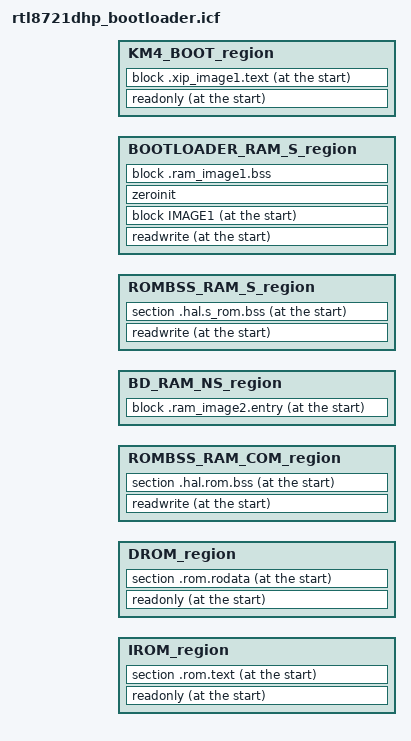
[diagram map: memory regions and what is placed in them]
/*###ICF### Section handled by ICF editor, don't touch! ****/
/*-Editor annotation file-*/
/* IcfEditorFile="$TOOLKIT_DIR$\config\ide\IcfEditor\cortex_v1_0.xml" */
/*-Specials-*/

include "rtl8721dhp_rom_symbol_boot.icf";
include "rtl8721d_memory_layout_tz.icf";

/*-Sizes-*/
/*define symbol __ICFEDIT_size_cstack__   = 0x400;*/
/*define symbol __ICFEDIT_size_heap__     = 0x800;*/
/**** End of ICF editor section. ###ICF###*/

define memory mem with size = 4G;
define region IROM_region   		= mem:[from __ICFEDIT_region_HS_IROM_start__   to __ICFEDIT_region_HS_IROM_end__];
define region IROM_NS_region   		= mem:[from __ICFEDIT_region_HS_IROM_NS_start__   to __ICFEDIT_region_HS_IROM_NS_end__];
define region DROM_NS_region   		= mem:[from __ICFEDIT_region_HS_DROM_NS_start__   to __ICFEDIT_region_HS_DROM_NS_end__];
define region DROM_region  		= mem:[from __ICFEDIT_region_HS_DROM_start__   to __ICFEDIT_region_HS_DROM_end__];
define region ROMBSS_RAM_COM_region   	= mem:[from __ICFEDIT_region_HS_ROMBSS_RAM_COM_start__   to __ICFEDIT_region_HS_ROMBSS_RAM_COM_end__];
define region ROMBSS_RAM_NS_region   	= mem:[from __ICFEDIT_region_HS_ROMBSS_RAM_NS_start__   to __ICFEDIT_region_HS_ROMBSS_RAM_NS_end__];
define region RSVD_RAM_NS_region   	= mem:[from __ICFEDIT_region_HS_RSVD_RAM_NS_start__   to __ICFEDIT_region_HS_RSVD_RAM_NS_end__];
define region MSP_RAM_NS_region   	= mem:[from __ICFEDIT_region_HS_MSP_RAM_NS_start__   to __ICFEDIT_region_HS_MSP_RAM_NS_end__];
define region BD_RAM_NS_region   	= mem:[from __ICFEDIT_region_HS_BD_RAM_NS_start__   to __ICFEDIT_region_HS_BD_RAM_NS_end__];
define region BD_RAM_S_region   	= mem:[from __ICFEDIT_region_HS_BD_RAM_S_start__   to __ICFEDIT_region_HS_BD_RAM_S_end__];
define region BD_RAM_NSC_region   	= mem:[from __ICFEDIT_region_HS_BD_RAM_NSC_start__   to __ICFEDIT_region_HS_BD_RAM_NSC_end__];
define region ROMBSS_RAM_S_region   	= mem:[from __ICFEDIT_region_HS_ROMBSS_RAM_S_start__   to __ICFEDIT_region_HS_ROMBSS_RAM_S_end__];
define region BOOTLOADER_RAM_S_region   = mem:[from __ICFEDIT_region_HS_BOOTLOADER_RAM_S_start__   to __ICFEDIT_region_HS_BOOTLOADER_RAM_S_end__];
define region MSP_RAM_S_region   	= mem:[from __ICFEDIT_region_HS_MSP_RAM_S_start__   to __ICFEDIT_region_HS_MSP_RAM_S_end__];
define region EXTENTION_SRAM_region   	= mem:[from __ICFEDIT_region_HS_EXTENTION_SRAM_start__   to __ICFEDIT_region_HS_EXTENTION_SRAM_end__];
define region PSRAM_region   		= mem:[from __ICFEDIT_region_HS_PSRAM_NS_start__   to __ICFEDIT_region_HS_PSRAM_NS_end__];
define region KM4_BOOT_region   	= mem:[from __ICFEDIT_region_HS_FLASH_BOOT_start__   to __ICFEDIT_region_HS_FLASH_BOOT_end__];
define region KM4_IMG2_region   	= mem:[from __ICFEDIT_region_HS_FLASH_IMG2_start__   to __ICFEDIT_region_HS_FLASH_IMG2_end__];
define region BTRACE_region   		= mem:[from __ICFEDIT_region_HS_BTRACE_start__   to __ICFEDIT_region_HS_BTRACE_end__];
define region RETENTION_RAM_region   	= mem:[from __ICFEDIT_region_RETENTION_RAM_start__   to __ICFEDIT_region_RETENTION_RAM_end__];


/*define block CSTACK    with alignment = 8, size = __ICFEDIT_size_cstack__   { };*/
/*define block HEAP      with alignment = 8, size = __ICFEDIT_size_heap__     { };*/

//initialize by copy { readwrite };
//initialize by copy with packing = none { section __DLIB_PERTHREAD }; // Required in a multi-threaded application

//do not initialize  { section * };
do not initialize { readwrite };

/****************************************
 * ROM Section config                   *
 ****************************************/
keep { section .rom.text };
place at start of IROM_region   { readonly, section .rom.text };

keep { section .rom.rodata };
place at start of DROM_region   { readonly, section .rom.rodata };

/****************************************
 * ROM BSS Section config                *
 ****************************************/
keep { section .hal.rom.bss };
place at start of ROMBSS_RAM_COM_region  { readwrite, section .hal.rom.bss };

keep { section .hal.s_rom.bss };
place at start of ROMBSS_RAM_S_region  { readwrite, section .hal.s_rom.bss };

/****************************************
 * BOOT RAM Section config                *
 ****************************************/
keep { section .image1.entry.data* };
keep { section .image1.validate.rodata* };
define block .ram_image1.entry with fixed order{section .image1.entry.data*,
						section .image1.validate.rodata*,
						section .image1.export.symb*,
						};

keep { section .boot.ram.text* };
keep { section .boot.rodata* };
define block .ram_image1.text with fixed order{section .boot.ram.text*,
						section .boot.rodata*,
						section .text*,
						section .rodata*,
                                                section CODE,                                                
						};

keep { section .boot.ram.data* };
define block .ram_image1.data with fixed order{section .boot.ram.data*,
						section .data*,
						section DATA, 
						section .iar.init_table,
						section __DLIB_PERTHREAD,
						};

keep { section .boot.ram.bss* };
keep { section .boot.ram.end.bss* };
define block .ram_image1.bss with fixed order{section .boot.ram.bss*,
                                              section .boot.ram.end.bss*,
                                              section .bss*,
					      section COMMON,
					      };


define block IMAGE1 with fixed order { block .ram_image1.entry, block .ram_image1.text, block .ram_image1.data};
place at start of BOOTLOADER_RAM_S_region   { readwrite, 
                                    block IMAGE1,
                                  };
                                  
place in BOOTLOADER_RAM_S_region {zeroinit,
                                    block .ram_image1.bss};

/****************************************
 * BD RAM NS Section config                *
 ****************************************/
keep { section .image2.entry.data* };
keep { section .image2.validate.rodata* };
define block .ram_image2.entry with fixed order{ section .image2.entry.data*,
						 section .image2.validate.rodata*,
						};
                                                
place at start of BD_RAM_NS_region { block .ram_image2.entry };

/****************************************
 * XIP BOOT Section config                *
 ****************************************/
keep { section .flashboot.text* };
define block .xip_image1.text with fixed order{ section .flashboot.text* };

place at start of KM4_BOOT_region   {  readonly,
					 block .xip_image1.text };

//define exported symbol __ram_start_table_start__= 0x10002000;	// use in rom
//define exported symbol __image1_validate_code__= 0x10002018;	// needed by ram code
//define exported symbol __rom_top_4k_start_= 0x1003F000;	// needed by ram code
//define exported symbol __flash_text_start__= 0x0800b020; // needed by ram code

define exported symbol __ram_image3_start__=__ICFEDIT_region_HS_BD_RAM_S_start__;
define exported symbol __ram_image3_end__=__ICFEDIT_region_HS_BD_RAM_S_end__ + 1;
define exported symbol __flash_text_start__=__ICFEDIT_region_HS_FLASH_IMG2_start__;

define exported symbol __psram_image3_start__=__ICFEDIT_region_HS_PSRAM_S_start__;
define exported symbol __psram_image3_end__=__ICFEDIT_region_HS_PSRAM_S_end__ + 1;
